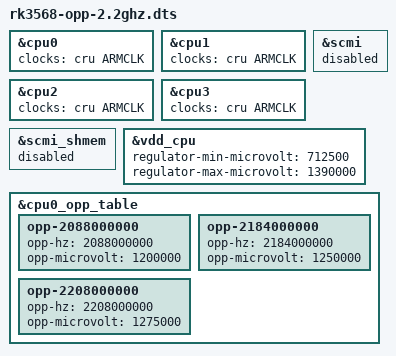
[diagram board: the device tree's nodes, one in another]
/dts-v1/;
/plugin/;

#include <dt-bindings/clock/rk3568-cru.h>

/ {
	fragment@0 {
		target = <&cpu0>;
		__overlay__ {
			clocks = <&cru ARMCLK>;
		};
	};

	fragment@1 {
		target = <&cpu1>;
		__overlay__ {
			clocks = <&cru ARMCLK>;
		};
	};

	fragment@2 {
		target = <&cpu2>;
		__overlay__ {
			clocks = <&cru ARMCLK>;
		};
	};

	fragment@3 {
		target = <&cpu3>;
		__overlay__ {
			clocks = <&cru ARMCLK>;
		};
	};

	fragment@4 {
		target = <&scmi>;
		__overlay__ {
			status = "diabled";
		};
	};

	fragment@5 {
		target = <&scmi_shmem>;
		__overlay__ {
			status = "diabled";
		};
	};

	fragment@6 {
		target = <&vdd_cpu>;
		__overlay__ {
			regulator-min-microvolt = <712500>;
			regulator-max-microvolt = <1390000>;
		};
	};

	fragment@7 {
		target = <&cpu0_opp_table>;
		__overlay__ {
			opp-2088000000 {
				opp-hz = /bits/ 64 <2088000000>;
				opp-microvolt = <1200000>;
			};

			opp-2184000000 {
				opp-hz = /bits/ 64 <2184000000>;
				opp-microvolt = <1250000>;
			};

			opp-2208000000 {
				opp-hz = /bits/ 64 <2208000000>;
				opp-microvolt = <1275000>;
			};
			
		};
	};
};
